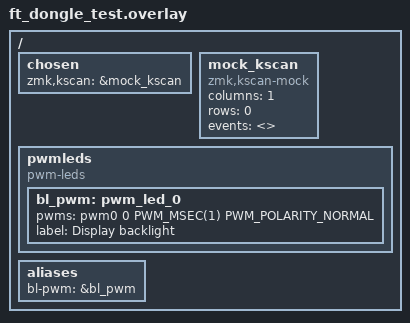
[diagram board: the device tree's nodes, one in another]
/*
 * FT Dongle Test - minimalny shield do testu PWM backlight
 * Tylko PWM na D5 (P0.24) + minimalny mock kscan żeby ZMK się skompilowało
 */

#include <dt-bindings/zmk/matrix_transform.h>

/ {
    chosen {
        zmk,kscan = &mock_kscan;
    };

    /* Fake kscan - ZMK wymaga jakiegokolwiek kscan + matrix transform */
    mock_kscan: mock_kscan {
        compatible = "zmk,kscan-mock";
        columns = <1>;
        rows = <0>;
        events = <>;
    };

    pwmleds {
        compatible = "pwm-leds";
        bl_pwm: pwm_led_0 {
            pwms = <&pwm0 0 PWM_MSEC(1) PWM_POLARITY_NORMAL>;
            label = "Display backlight";
        };
    };

    aliases {
        bl-pwm = &bl_pwm;
    };
};
